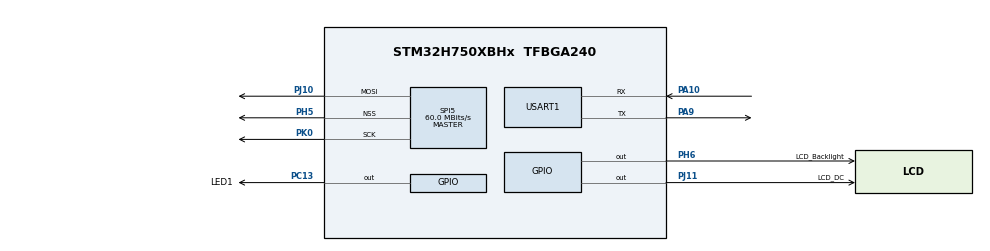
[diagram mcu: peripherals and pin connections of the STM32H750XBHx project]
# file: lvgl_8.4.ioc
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CORTEX_M7.CPU_DCache=Enabled
CORTEX_M7.CPU_ICache=Enabled
Mcu.Family=STM32H7
Mcu.Name=STM32H750XBHx
Mcu.Package=TFBGA240
NVIC.PriorityGroup=NVIC_PRIORITYGROUP_4
PA10.GPIO_Speed=GPIO_SPEED_FREQ_VERY_HIGH
PA10.Mode=Asynchronous
PA10.Signal=USART1_RX
PA13\ (JTMS/SWDIO).Mode=Serial_Wire
PA13\ (JTMS/SWDIO).Signal=DEBUG_JTMS-SWDIO
PA14\ (JTCK/SWCLK).Mode=Serial_Wire
PA14\ (JTCK/SWCLK).Signal=DEBUG_JTCK-SWCLK
PA9.GPIO_Speed=GPIO_SPEED_FREQ_VERY_HIGH
PA9.Mode=Asynchronous
PA9.Signal=USART1_TX
PC13.GPIO_Label=LED1
PC13.Signal=GPIO_Output
PC14-OSC32_IN\ (OSC32_IN).Mode=LSE-External-Oscillator
PC14-OSC32_IN\ (OSC32_IN).Signal=RCC_OSC32_IN
PC15-OSC32_OUT\ (OSC32_OUT).Mode=LSE-External-Oscillator
PC15-OSC32_OUT\ (OSC32_OUT).Signal=RCC_OSC32_OUT
PH0-OSC_IN\ (PH0).Mode=HSE-External-Oscillator
PH0-OSC_IN\ (PH0).Signal=RCC_OSC_IN
PH1-OSC_OUT\ (PH1).Mode=HSE-External-Oscillator
PH1-OSC_OUT\ (PH1).Signal=RCC_OSC_OUT
PH5.GPIO_Speed=GPIO_SPEED_FREQ_VERY_HIGH
PH5.Mode=NSS_Signal_Hard_Output
PH5.Signal=SPI5_NSS
PH6.GPIO_Label=LCD_Backlight
PH6.GPIO_PuPd=GPIO_PULLDOWN
PH6.GPIO_Speed=GPIO_SPEED_FREQ_VERY_HIGH
PH6.Signal=GPIO_Output
PJ10.GPIO_Speed=GPIO_SPEED_FREQ_VERY_HIGH
PJ10.Mode=TX_Only_Simplex_Unidirect_Master
PJ10.Signal=SPI5_MOSI
PJ11.GPIO_Label=LCD_DC
PJ11.GPIO_Speed=GPIO_SPEED_FREQ_VERY_HIGH
PJ11.Signal=GPIO_Output
PK0.GPIO_Speed=GPIO_SPEED_FREQ_VERY_HIGH
PK0.Mode=TX_Only_Simplex_Unidirect_Master
PK0.Signal=SPI5_SCK
ProjectManager.HeapSize=0x1000
ProjectManager.StackSize=0x1000
ProjectManager.TargetToolchain=STM32CubeIDE
RCC.ADCFreq_Value=50390625
RCC.APB1Freq_Value=120000000
RCC.APB2Freq_Value=120000000
RCC.APB3Freq_Value=120000000
RCC.APB4Freq_Value=120000000
RCC.CortexFreq_Value=480000000
RCC.D1PPRE=RCC_APB3_DIV2
RCC.D2PPRE1=RCC_APB1_DIV2
RCC.D2PPRE2=RCC_APB2_DIV2
RCC.D3PPRE=RCC_APB4_DIV2
RCC.DIVM1=5
RCC.DIVN1=192
RCC.HCLKFreq_Value=240000000
RCC.HPRE=RCC_HCLK_DIV2
RCC.PLLFRACN=0
RCC.PLLSourceVirtual=RCC_PLLSOURCE_HSE
RCC.SYSCLKFreq_VALUE=480000000
RCC.SYSCLKSource=RCC_SYSCLKSOURCE_PLLCLK
RCC.USBFreq_Value=480000000
SPI5.CalculateBaudRate=60.0 MBits/s
SPI5.DataSize=SPI_DATASIZE_8BIT
SPI5.Direction=SPI_DIRECTION_2LINES_TXONLY
SPI5.Mode=SPI_MODE_MASTER
SPI5.VirtualNSS=VM_NSSHARD
SPI5.VirtualType=VM_MASTER
USART1.VirtualMode-Asynchronous=VM_ASYNC
VP_MEMORYMAP_VS_MEMORYMAP.Mode=CurAppReg
board=custom

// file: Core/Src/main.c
/* USER CODE BEGIN Header */
/**
  ******************************************************************************
  * @file           : main.c
  * @brief          : Main program body
  ******************************************************************************
  * @attention
  *
  * Copyright (c) 2024 STMicroelectronics.
  * All rights reserved.
  *
  * This software is licensed under terms that can be found in the LICENSE file
  * in the root directory of this software component.
  * If no LICENSE file comes with this software, it is provided AS-IS.
  *
  ******************************************************************************
  */
/* USER CODE END Header */
#include "main.h"
#include "memorymap.h"
#include "spi.h"
#include "usart.h"
#include "gpio.h"

/* USER CODE BEGIN PV */
uint16_t color[26] = {
		RED, RED, RED, RED, RED,
		RED, RED, RED, RED, RED,
		RED, RED, RED, RED, RED,
		RED, RED, RED, RED, RED,
		RED, RED, RED, RED, RED
};
/* USER CODE END PV */

void SystemClock_Config(void);

int main(void)
{

	/* Enable the CPU Cache */

	/* Enable I-Cache---------------------------------------------------------*/
	SCB_EnableICache();

	/* Enable D-Cache---------------------------------------------------------*/
	SCB_EnableDCache();

	/* MCU Configuration--------------------------------------------------------*/

	/* Reset of all peripherals, Initializes the Flash interface and the Systick. */
	HAL_Init();

	/* Configure the system clock */
	SystemClock_Config();

	/* Initialize all configured peripherals */
	MX_GPIO_Init();
	MX_SPI5_Init();
	MX_USART1_UART_Init();
	/* USER CODE BEGIN 2 */
	RetargetInit(&huart1);
	lv_init();                                  /* lvgl系统初始化 */
	lv_port_disp_init();                        /* lvgl显示接口初始化,放在lv_init()的后面 */
	lv_demo_benchmark();
	/* USER CODE END 2 */

	/* Infinite loop */
	/* USER CODE BEGIN WHILE */
	while (1)
	{
//		LED1_Toggle;
//		printf("test\r\n");
//		HAL_Delay(300);
		lv_task_handler();
		/* USER CODE END WHILE */

	}
}

void SystemClock_Config(void)
{
	RCC_OscInitTypeDef RCC_OscInitStruct = {0};
	RCC_ClkInitTypeDef RCC_ClkInitStruct = {0};

	/** Supply configuration update enable
	*/
	HAL_PWREx_ConfigSupply(PWR_LDO_SUPPLY);

	/** Configure the main internal regulator output voltage
	*/
	__HAL_PWR_VOLTAGESCALING_CONFIG(PWR_REGULATOR_VOLTAGE_SCALE1);

	while (!__HAL_PWR_GET_FLAG(PWR_FLAG_VOSRDY))
	{
	}

	__HAL_RCC_SYSCFG_CLK_ENABLE();
	__HAL_PWR_VOLTAGESCALING_CONFIG(PWR_REGULATOR_VOLTAGE_SCALE0);

	while (!__HAL_PWR_GET_FLAG(PWR_FLAG_VOSRDY))
	{
	}

	/** Initializes the RCC Oscillators according to the specified parameters
	* in the RCC_OscInitTypeDef structure.
	*/
	RCC_OscInitStruct.OscillatorType = RCC_OSCILLATORTYPE_HSE;
	RCC_OscInitStruct.HSEState = RCC_HSE_ON;
	RCC_OscInitStruct.PLL.PLLState = RCC_PLL_ON;
	RCC_OscInitStruct.PLL.PLLSource = RCC_PLLSOURCE_HSE;
	RCC_OscInitStruct.PLL.PLLM = 5;
	RCC_OscInitStruct.PLL.PLLN = 192;
	RCC_OscInitStruct.PLL.PLLP = 2;
	RCC_OscInitStruct.PLL.PLLQ = 2;
	RCC_OscInitStruct.PLL.PLLR = 2;
	RCC_OscInitStruct.PLL.PLLRGE = RCC_PLL1VCIRANGE_2;
	RCC_OscInitStruct.PLL.PLLVCOSEL = RCC_PLL1VCOWIDE;
	RCC_OscInitStruct.PLL.PLLFRACN = 0;
	if (HAL_RCC_OscConfig(&RCC_OscInitStruct) != HAL_OK)
	{
		Error_Handler();
	}

	/** Initializes the CPU, AHB and APB buses clocks
	*/
	RCC_ClkInitStruct.ClockType = RCC_CLOCKTYPE_HCLK | RCC_CLOCKTYPE_SYSCLK
								  | RCC_CLOCKTYPE_PCLK1 | RCC_CLOCKTYPE_PCLK2
								  | RCC_CLOCKTYPE_D3PCLK1 | RCC_CLOCKTYPE_D1PCLK1;
	RCC_ClkInitStruct.SYSCLKSource = RCC_SYSCLKSOURCE_PLLCLK;
	RCC_ClkInitStruct.SYSCLKDivider = RCC_SYSCLK_DIV1;
	RCC_ClkInitStruct.AHBCLKDivider = RCC_HCLK_DIV2;
	RCC_ClkInitStruct.APB3CLKDivider = RCC_APB3_DIV2;
	RCC_ClkInitStruct.APB1CLKDivider = RCC_APB1_DIV2;
	RCC_ClkInitStruct.APB2CLKDivider = RCC_APB2_DIV2;
	RCC_ClkInitStruct.APB4CLKDivider = RCC_APB4_DIV2;

	if (HAL_RCC_ClockConfig(&RCC_ClkInitStruct, FLASH_LATENCY_4) != HAL_OK)
	{
		Error_Handler();
	}
}

void Error_Handler(void)
{
	__disable_irq();
	while (1)
	{
	}
}
